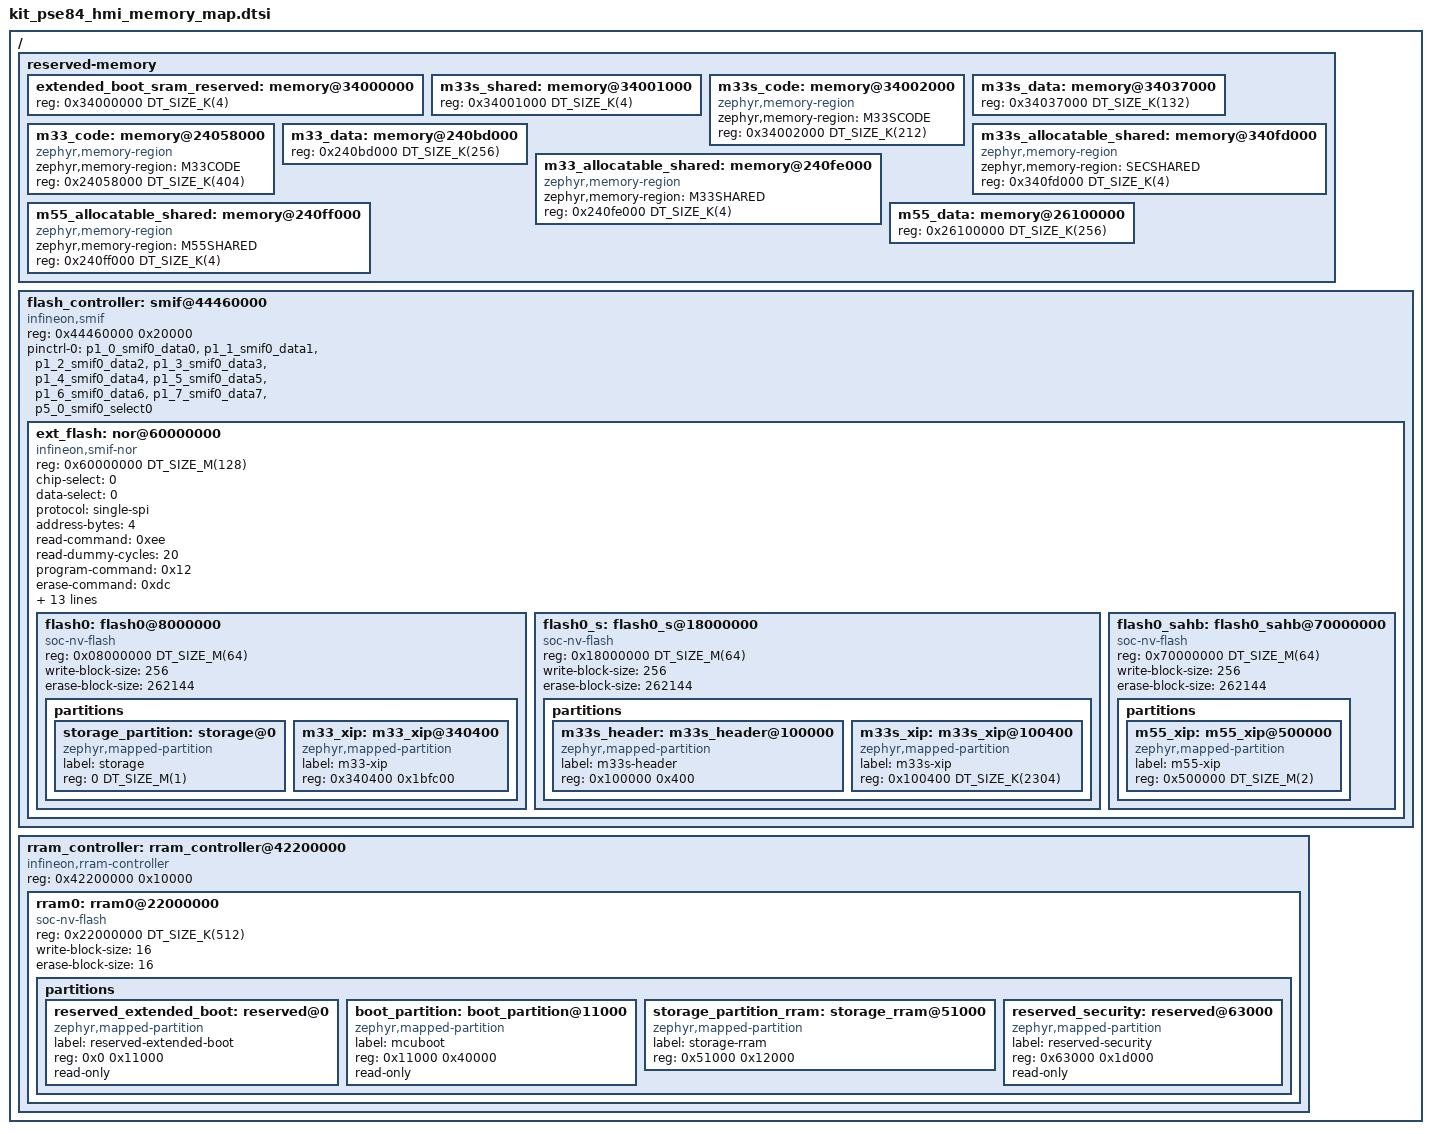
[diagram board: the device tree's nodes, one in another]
/*
 * SPDX-FileCopyrightText: Copyright (c) 2026 Infineon Technologies AG,
 * SPDX-FileCopyrightText: or an affiliate of Infineon Technologies AG. All rights reserved.
 *
 * SPDX-License-Identifier: Apache-2.0
 */

/ {
	/* Default SRAM(1MB) assignment
	 * - Lowest 4kb reserved for the Extended boot
	 * - 4kb shared between CM33 secure project and secure enclave
	 * - 212 kB allocated to CM33 Secure code
	 * - 132 kB allocated to CM33 Secure data
	 * - 404 kB allocated to CM33 Non-Secure code
	 * - 256 kB allocated to the CM33 Non-Secure data
	 * - 4 kB allocated to shared memory for each core (cm33_s, cm33 and cm55)
	 */
	reserved-memory {
		#address-cells = <1>;
		#size-cells = <1>;
		ranges;

		extended_boot_sram_reserved: memory@34000000 {
			reg = <0x34000000 DT_SIZE_K(4)>;
		};

		m33s_shared: memory@34001000 {
			reg = <0x34001000 DT_SIZE_K(4)>;
		};

		m33s_code: memory@34002000 {
			compatible = "zephyr,memory-region", "mmio-sram";
			zephyr,memory-region = "M33SCODE";
			reg = <0x34002000 DT_SIZE_K(212)>;
		};

		m33s_data: memory@34037000 {
			reg = <0x34037000 DT_SIZE_K(132)>;
		};

		m33_code: memory@24058000 {
			compatible = "zephyr,memory-region", "mmio-sram";
			zephyr,memory-region = "M33CODE";
			reg = <0x24058000 DT_SIZE_K(404)>;
		};

		m33_data: memory@240bd000 {
			reg = <0x240bd000 DT_SIZE_K(256)>;
		};

		m33s_allocatable_shared: memory@340fd000 {
			compatible = "zephyr,memory-region", "mmio-sram";
			zephyr,memory-region = "SECSHARED";
			reg = <0x340fd000 DT_SIZE_K(4)>;
		};

		m33_allocatable_shared: memory@240fe000 {
			compatible = "zephyr,memory-region", "mmio-sram";
			zephyr,memory-region = "M33SHARED";
			reg = <0x240fe000 DT_SIZE_K(4)>;
		};

		m55_allocatable_shared: memory@240ff000 {
			compatible = "zephyr,memory-region", "mmio-sram";
			zephyr,memory-region = "M55SHARED";
			reg = <0x240ff000 DT_SIZE_K(4)>;
		};

		m55_data: memory@26100000 {
			reg = <0x26100000 DT_SIZE_K(256)>;
		};
	};

	/* Default Flash memory(16MB) assignment
	 * - 1 MB  reserved for Storage
	 * - 1 KB  header for CM33 Secure
	 * - 2304 KB allocated to CM33 Secure XIP
	 * - 1791 KB allocated to CM33 Non-Secure XIP
	 * - 2 MB  allocated to CM55 XIP
	 *
	 * Each code-partition uses zephyr,mapped-partition under the flash
	 * alias whose base address matches the executing core's view.
	 */
	flash_controller: smif@44460000 {
		compatible = "infineon,smif";
		reg = <0x44460000 0x20000>;
		#address-cells = <1>;
		#size-cells = <1>;
		ranges;

		pinctrl-0 = <&p1_0_smif0_data0 &p1_1_smif0_data1
			     &p1_2_smif0_data2 &p1_3_smif0_data3
			     &p1_4_smif0_data4 &p1_5_smif0_data5
			     &p1_6_smif0_data6 &p1_7_smif0_data7
			     &p5_0_smif0_select0>;
		pinctrl-names = "default";
		status = "okay";

		/* External NOR flash device on SMIF0 chip-select 0 in octal
		 * double-data-rate (8D-8D-8D) mode (Infineon S28HS01GT, Semper
		 * Secure NOR, 1 Gbit / 128 MiB). The extended boot brings SMIF0
		 * up in octal XIP mode when booting from this device, so the
		 * controller is not re-initialised here. Program and erase use
		 * SMIF command mode; the command set, geometry and octal-enable
		 * sequence are described statically below and mirror the QSPI
		 * Configurator output for the part.
		 *
		 * The three soc-nv-flash views below expose the same physical
		 * device through the CBUS-NS, CBUS-S and SAHB address windows,
		 * each selected as zephyr,flash for the corresponding core build.
		 */
		ext_flash: nor@60000000 {
			compatible = "infineon,smif-nor";
			reg = <0x60000000 DT_SIZE_M(128)>;
			#address-cells = <1>;
			#size-cells = <1>;
			ranges;
			chip-select = <0>;
			data-select = <0>;
			/* The protocol for this memory is actually ospi but the driver
			 * does not support it yet so for now it's set to single-spi.
			 */
			protocol = "single-spi";
			address-bytes = <4>;
			read-command = <0xee>;
			read-dummy-cycles = <20>;
			program-command = <0x12>;
			erase-command = <0xdc>;
			page-size = <256>;
			erase-time-ms = <5869>;
			chip-erase-time-ms = <1381000>;
			program-time-us = <2175>;
			write-block-size = <16>;
			erase-block-size = <DT_SIZE_K(256)>;
			hybrid-region-address = <0x0 0x20000 0x40000>;
			hybrid-region-sectors = <32 1 511>;
			hybrid-region-erase-command = <0x21 0xdc 0xdc>;
			hybrid-region-erase-size = <0x1000 0x20000 0x40000>;
			hybrid-region-erase-time-ms = <335 5869 5869>;
			memory-mapped;
			status = "okay";

			/* CBUS non-secure view (base 0x08000000); zephyr,flash for NS. */
			flash0: flash0@8000000 {
				compatible = "soc-nv-flash", "infineon,s28hs01gt";
				reg = <0x08000000 DT_SIZE_M(64)>;
				#address-cells = <1>;
				#size-cells = <1>;
				ranges = <0x0 0x08000000 DT_SIZE_M(64)>;
				write-block-size = <256>;
				erase-block-size = <262144>;

				partitions {
					#address-cells = <1>;
					#size-cells = <1>;
					ranges;

					storage_partition: storage@0 {
						compatible = "zephyr,mapped-partition";
						label = "storage";
						reg = <0 DT_SIZE_M(1)>;
					};

					m33_xip: m33_xip@340400 {
						compatible = "zephyr,mapped-partition";
						label = "m33-xip";
						reg = <0x340400 0x1bfc00>;
					};
				};
			};

			/* CBUS secure view (base 0x18000000); zephyr,flash for S. */
			flash0_s: flash0_s@18000000 {
				compatible = "soc-nv-flash";
				reg = <0x18000000 DT_SIZE_M(64)>;
				#address-cells = <1>;
				#size-cells = <1>;
				ranges = <0x0 0x18000000 DT_SIZE_M(64)>;
				write-block-size = <256>;
				erase-block-size = <262144>;

				partitions {
					#address-cells = <1>;
					#size-cells = <1>;
					ranges;

					m33s_header: m33s_header@100000 {
						compatible = "zephyr,mapped-partition";
						label = "m33s-header";
						reg = <0x100000 0x400>;
					};

					m33s_xip: m33s_xip@100400 {
						compatible = "zephyr,mapped-partition";
						label = "m33s-xip";
						reg = <0x100400 DT_SIZE_K(2304)>;
					};
				};
			};

			/* SAHB view (base 0x70000000); zephyr,flash for CM55. */
			flash0_sahb: flash0_sahb@70000000 {
				compatible = "soc-nv-flash";
				reg = <0x70000000 DT_SIZE_M(64)>;
				#address-cells = <1>;
				#size-cells = <1>;
				ranges = <0x0 0x70000000 DT_SIZE_M(64)>;
				write-block-size = <256>;
				erase-block-size = <262144>;

				partitions {
					#address-cells = <1>;
					#size-cells = <1>;
					ranges;

					m55_xip: m55_xip@500000 {
						compatible = "zephyr,mapped-partition";
						label = "m55-xip";
						reg = <0x500000 DT_SIZE_M(2)>;
					};
				};
			};
		};
	};

	/* RRAM memory (512 KB) assignment
	 *   0x00000 - 0x10FFF : reserved-extended-boot (68 KB)
	 *   0x11000 - 0x50FFF : boot_partition (256 KB) - MCUBoot bootloader
	 *   0x51000 - 0x62FFF : storage_rram (72 KB)
	 *   0x63000 - 0x7FFFF : reserved-security (116 KB)
	 */
	rram_controller: rram_controller@42200000 {
		compatible = "infineon,rram-controller";
		reg = <0x42200000 0x10000>;
		#address-cells = <1>;
		#size-cells = <1>;
		ranges;
		status = "okay";

		rram0: rram0@22000000 {
			compatible = "soc-nv-flash";
			reg = <0x22000000 DT_SIZE_K(512)>;
			#address-cells = <1>;
			#size-cells = <1>;
			ranges = <0x0 0x22000000 DT_SIZE_K(512)>;
			write-block-size = <16>;
			erase-block-size = <16>;
			status = "okay";

			partitions {
				#address-cells = <1>;
				#size-cells = <1>;
				ranges;

				reserved_extended_boot: reserved@0 {
					compatible = "zephyr,mapped-partition";
					label = "reserved-extended-boot";
					reg = <0x0 0x11000>;
					read-only;
				};

				boot_partition: boot_partition@11000 {
					compatible = "zephyr,mapped-partition";
					label = "mcuboot";
					reg = <0x11000 0x40000>;
					read-only;
				};

				storage_partition_rram: storage_rram@51000 {
					compatible = "zephyr,mapped-partition";
					label = "storage-rram";
					reg = <0x51000 0x12000>;
				};

				reserved_security: reserved@63000 {
					compatible = "zephyr,mapped-partition";
					label = "reserved-security";
					reg = <0x63000 0x1d000>;
					read-only;
				};
			};
		};
	};
};
